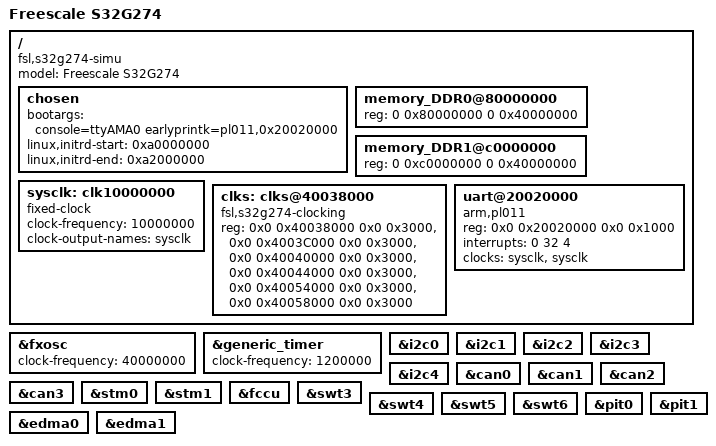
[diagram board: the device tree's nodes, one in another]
/*
 * Copyright 2017-2020 NXP
 *
 * This program is free software; you can redistribute it and/or modify
 * it under the terms of the GNU General Public License as published by
 * the Free Software Foundation; either version 2 of the License, or
 * (at your option) any later version.
 */

/dts-v1/;
#include "fsl-s32g274a.dtsi"
#include <dt-bindings/pinctrl/s32g274-pinctrl.h>
/ {
	model = "Freescale S32G274";
	compatible = "fsl,s32g274-simu", "fsl,s32g274",
				 "arm,vexpress,v2p-aarch64", "arm,vexpress";

	chosen {
		bootargs = "console=ttyAMA0 earlyprintk=pl011,0x20020000";
		linux,initrd-start = <0xa0000000>;
		linux,initrd-end = <0xa2000000>;

	};

	memory_DDR0@80000000 {
		device_type = "memory";
		reg = <0 0x80000000 0 0x40000000>;
	};

	memory_DDR1@c0000000 {
		device_type = "memory";
		reg = <0 0xc0000000 0 0x40000000>;
	};

	sysclk: clk10000000 {
		compatible = "fixed-clock";
		#clock-cells = <0>;
		clock-frequency = <10000000>;
		clock-output-names = "sysclk";
	};

	clks: clks@40038000 {
		compatible = "fsl,s32g274-clocking";
		reg = <0x0 0x40038000 0x0 0x3000>, /*armpll*/
		      <0x0 0x4003C000 0x0 0x3000>, /*periphpll*/
		      <0x0 0x40040000 0x0 0x3000>, /*accelpll*/
		      <0x0 0x40044000 0x0 0x3000>, /*ddrpll*/
		      <0x0 0x40054000 0x0 0x3000>, /*armdfs*/
		      <0x0 0x40058000 0x0 0x3000>; /*periphdfs*/
		#clock-cells = <1>;
	};

	uart@20020000 {
		compatible = "arm,pl011", "arm,primecell";
		reg = <0x0 0x20020000 0x0 0x1000>;
		interrupts = <0 32 4>;
		clock-names = "uartclk", "apb_pclk";
		clocks = <&sysclk>, <&sysclk>;
	};
};

&fxosc {
	clock-frequency = <40000000>;
};

&generic_timer {
	clock-frequency = <1200000>;
};

&i2c0 {
	status = "okay";
};

&i2c1 {
	status = "okay";
};

&i2c2 {
	status = "okay";
};

&i2c3 {
	status = "okay";
};

&i2c4 {
	status = "okay";
};

&can0 {
	status = "okay";
};

&can1 {
	status = "okay";
};

&can2 {
	status = "okay";
};

&can3 {
	status = "okay";
};

&stm0 {
	status = "okay";
};

&stm1 {
	status = "okay";
};

&fccu {
	status = "okay";
};

&swt3 {
	status = "okay";
};

&swt4 {
	status = "okay";
};

&swt5 {
	status = "okay";
};

&swt6 {
	status = "okay";
};

&pit0 {
	status = "okay";
};

&pit1 {
	status = "okay";
};

&edma0 {
	status = "okay";
};

&edma1 {
	status = "okay";
};
